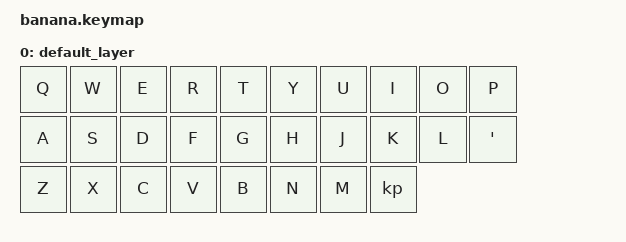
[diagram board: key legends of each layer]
#include <behaviors.dtsi>
#include <dt-bindings/zmk/keys.h>

/ {
    keymap {
        compatible = "zmk,keymap";

        default_layer {
			// Layer 0: Base keys
			//
			// ,-----.-----.-----.-----.-----.    ,-----.-----.-----.-----.-----.
			// | Q   | W   | E   | R   | T   |    | Y   | U   | I   | O   | P   |
			// |-----+-----+-----+-----+-----|    |-----+-----+-----+-----+-----|
			// | A   | S   | D   | F   | G   |    | H   | J   | K   | L   | ' " | 
			// |-----+-----+-----+-----+-----+    |-----+-----+-----+-----+-----|
			// |SHF/Z| X   | C   | V   | B   |    | N   | M   | < , | > . |SHF/?|
			// `-----'-----'-----'-----'-----'    `-----'-----'-----'-----'-----'
			//        .-------.-------.-------.  .-------.-------.-------.   
			//        |ALT/ESC|  WIN  |CTR/TAB|  | ENTER |L1/SPC |L2/BSP |
			//        '-------'-------'-------'  '-------'-------'-------' 
             bindings = <
                &kp Q    &kp W    &kp E    &kp R    &kp T    &kp Y    &kp U    &kp I    &kp O    &kp P
				&kp A    &kp S    &kp D    &kp F    &kp G    &kp H    &kp J    &kp K    &kp L    &kp APOSTROPHE
                &kp Z    &kp X    &kp C    &kp V    &kp B    &kp N    &kp M     &kp
            >;
			// Layer 1: Symbols
			// ,-----.-----.-----.-----.-----.    ,-----.-----.-----.-----.-----.
			// | 1!  | 2@  | 3#  | 4$  | 5%  |    | 6^  | 7&  | 8*  | 9(  | 0)  |
			// |-----+-----+-----+-----+-----|    |-----+-----+-----+-----+-----|
			// | `~  |HOME |PGUP |PGDN | END |    |LEFT |DOWN | UP  |RGHT | ;:  |
			// |-----+-----+-----+-----+-----+    |-----+-----+-----+-----+-----|
			// |SHFT |     |     |     |     |    | -_  | =+  | [{  | ]}  |SHF\||
			// `-----'-----'-----'-----'-----'    `-----'-----'-----'-----'-----'
			//        .-------.-------.-------.      .-------.-------.-------.   
			//        |       |       |       |      |       |(hold) |       |
	        //        '-------'-------'-------'      '-------'-------'-------' 
			//
    };
};

